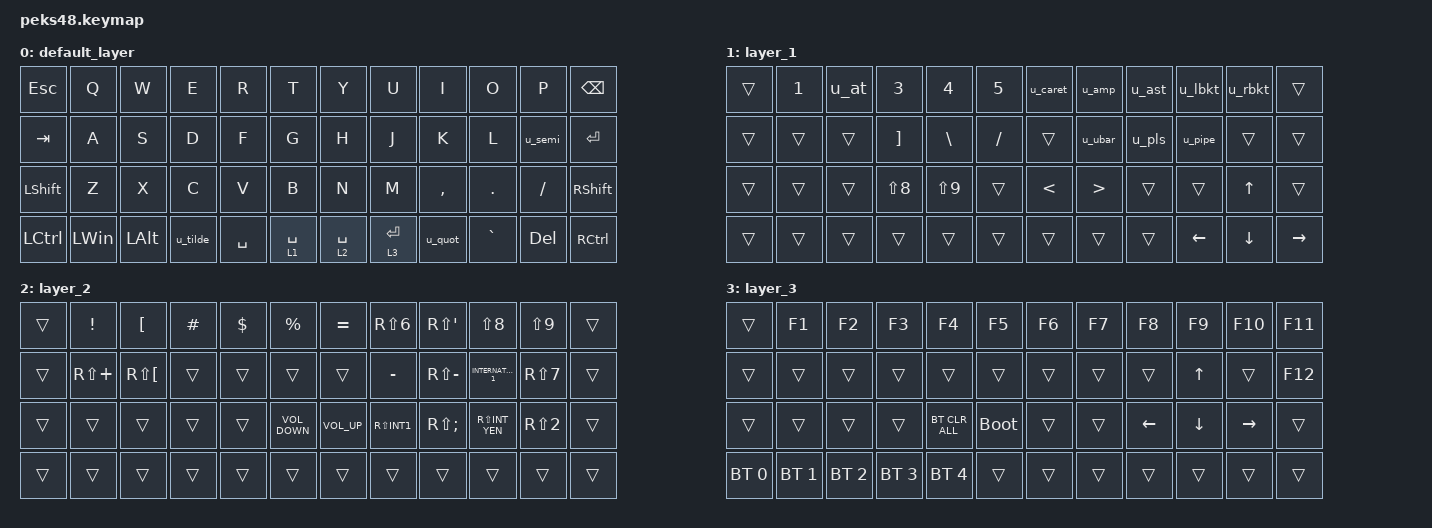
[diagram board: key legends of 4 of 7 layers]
#include <input/processors.dtsi>
#include <dt-bindings/zmk/input_transform.h>
#include <zephyr/dt-bindings/input/input-event-codes.h>
#include <behaviors.dtsi>
#include <dt-bindings/zmk/bt.h>
#include <dt-bindings/zmk/keys.h>
#include <dt-bindings/zmk/pointing.h>

// Conversion definition for using Japanese keyboard with OS settings

#define JP_DQUOTE       AT                // "
#define JP_AMPERSAND    CARET             // &
#define JP_QUOTE        AMPERSAND         // '
#define JP_EQUAL        UNDER             // =
#define JP_CARET        EQUAL             // ^
#define JP_YEN          0x89              // ¥
#define JP_PLUS         COLON             // +
#define JP_TILDE        PLUS              // ~
#define JP_PIPE         LS(0x89)          // |
#define JP_AT           LEFT_BRACKET      // @
#define JP_COLON        SINGLE_QUOTE      // :
#define JP_ASTERISK     DOUBLE_QUOTES     // *
#define JP_BACKQUOTE    LEFT_BRACE        // `
#define JP_UNDERSCORE   LS(0x87)          // _
#define JP_LBRACKET     RIGHT_BRACKET     // [
#define JP_RBRACKET     BACKSLASH         // ]
#define JP_LPAREN       ASTERISK          // (
#define JP_RPAREN       LEFT_PARENTHESIS  // )
#define JP_LBRACE       RIGHT_BRACE       // {
#define JP_RBRACE       PIPE              // }
#define JP_KANA         LANGUAGE_1        // かな
#define JP_EISU         LANGUAGE_2        // 英数
#define JP_HANZEN       GRAVE             // 半角/全角

&mt {
    flavor = "balanced";
    quick-tap-ms = <0>;
};

/ {
    behaviors {
        // 2 と @

        u_at: u_at {
            compatible = "zmk,behavior-mod-morph";
            #binding-cells = <0>;
            bindings = <&kp N2>, <&kp LBKT>;

            mods = <(MOD_LSFT|MOD_RSFT)>;
            label = "2";
        };

        // 6 と ^

        u_caret: u_caret {
            compatible = "zmk,behavior-mod-morph";
            #binding-cells = <0>;
            bindings = <&kp N6>, <&kp EQUAL>;

            mods = <(MOD_LSFT|MOD_RSFT)>;
            label = "6";
        };

        // 7 と &

        u_amp: u_amp {
            compatible = "zmk,behavior-mod-morph";
            #binding-cells = <0>;
            bindings = <&kp N7>, <&kp RS(N6)>;

            mods = <(MOD_LSFT|MOD_RSFT)>;
            label = "7";
        };

        // 8 と *

        u_ast: u_ast {
            compatible = "zmk,behavior-mod-morph";
            #binding-cells = <0>;
            bindings = <&kp N8>, <&kp LS(SQT)>;

            mods = <(MOD_LSFT|MOD_RSFT)>;
            label = "8";
        };

        // 9 と (

        u_lbkt: u_lbkt {
            compatible = "zmk,behavior-mod-morph";
            #binding-cells = <0>;
            bindings = <&kp N9>, <&kp RS(N8)>;

            mods = <(MOD_LSFT|MOD_RSFT)>;
            label = "9";
        };

        // 0 と )

        u_rbkt: u_rbkt {
            compatible = "zmk,behavior-mod-morph";
            #binding-cells = <0>;
            bindings = <&kp N0>, <&kp RS(N9)>;

            mods = <(MOD_LSFT|MOD_RSFT)>;
            label = "0";
        };

        // ; と : (US配列の ;/:)

        u_semi: u_semi {
            compatible = "zmk,behavior-mod-morph";
            #binding-cells = <0>;
            bindings = <&kp SEMI>, <&kp SQT>;

            mods = <(MOD_LSFT|MOD_RSFT)>;
            label = ";";
        };

        // ' と ~

        u_tilde: u_tilde {
            compatible = "zmk,behavior-mod-morph";
            #binding-cells = <0>;
            bindings = <&kp RS(LBKT)>, <&kp RS(PLUS)>;

            mods = <(MOD_LSFT|MOD_RSFT)>;
            label = "`~";
        };

        // ' と "

        u_quot: u_quot {
            compatible = "zmk,behavior-mod-morph";
            #binding-cells = <0>;
            bindings = <&kp RS(N7)>, <&kp RS(N2)>;

            mods = <(MOD_LSFT|MOD_RSFT)>;
            label = "'";
        };

        // - と _

        u_ubar: u_ubar {
            compatible = "zmk,behavior-mod-morph";
            #binding-cells = <0>;
            bindings = <&kp MINUS>, <&kp RS(INTERNATIONAL_1)>;

            mods = <(MOD_LSFT|MOD_RSFT)>;
            label = "-";
        };

        // = と +

        u_pls: u_pls {
            compatible = "zmk,behavior-mod-morph";
            #binding-cells = <0>;
            bindings = <&kp RS(MINUS)>, <&kp RS(SEMICOLON)>;

            mods = <(MOD_LSFT|MOD_RSFT)>;
            label = "=";
        };

        // \ と |

        u_pipe: u_pipe {
            compatible = "zmk,behavior-mod-morph";
            #binding-cells = <0>;
            bindings = <&kp INTERNATIONAL_1>, <&kp RS(INTERNATIONAL_3)>;

            mods = <(MOD_LSFT|MOD_RSFT)>;
            label = "bs";
        };
    };
};

/ {
    keymap {
        compatible = "zmk,keymap";

        default_layer {
            bindings = <
&kp ESC           &kp Q     &kp W         &kp E     &kp R      &kp T          &kp Y        &kp U        &kp I      &kp O      &kp P       &kp BACKSPACE
&kp TAB           &kp A     &kp S         &kp D     &kp F      &kp G          &kp H        &kp J        &kp K      &kp L      &u_semi     &kp ENTER
&kp LEFT_SHIFT    &kp Z     &kp X         &kp C     &kp V      &kp B          &kp N        &kp M        &kp COMMA  &kp DOT    &kp SLASH   &kp RSHIFT
&kp LEFT_CONTROL  &kp LWIN  &kp LEFT_ALT  &u_tilde  &kp SPACE  &lt 1 SPACE    &lt 2 SPACE  &lt 3 ENTER  &u_quot    &kp GRAVE  &kp DELETE  &kp RIGHT_CONTROL
            >;
        };

        layer_1 {
            bindings = <
&trans  &kp N1  &u_at   &kp N3      &kp N4      &kp N5       &u_caret  &u_amp            &u_ast  &u_lbkt         &u_rbkt         &trans
&trans  &trans  &trans  &kp RBKT    &kp BSLH    &kp SLASH    &trans    &u_ubar           &u_pls  &u_pipe         &trans          &trans
&trans  &trans  &trans  &kp LS(N8)  &kp LS(N9)  &trans       &kp LT    &kp GREATER_THAN  &trans  &trans          &kp UP_ARROW    &trans
&trans  &trans  &trans  &trans      &trans      &trans       &trans    &trans            &trans  &kp LEFT_ARROW  &kp DOWN_ARROW  &kp RIGHT_ARROW
            >;
        };

        layer_2 {
            bindings = <
&trans  &kp EXCLAMATION  &kp LBKT      &kp POUND  &kp DOLLAR  &kp PERCENT          &kp EQUAL        &kp RS(N6)    &kp RS(SQT)        &kp LS(N8)           &kp LS(N9)  &trans
&trans  &kp RS(PLUS)     &kp RS(LBKT)  &trans     &trans      &trans               &trans           &kp MINUS     &kp RS(MINUS)      &kp INTERNATIONAL_1  &kp RS(N7)  &trans
&trans  &trans           &trans        &trans     &trans      &kp C_VOLUME_DOWN    &kp C_VOLUME_UP  &kp RS(INT1)  &kp RS(SEMICOLON)  &kp RS(INT_YEN)      &kp RS(N2)  &trans
&trans  &trans           &trans        &trans     &trans      &trans               &trans           &trans        &trans             &trans               &trans      &trans
            >;
        };

        layer_3 {
            bindings = <
&trans        &kp F1        &kp F2        &kp F3        &kp F4          &kp F5         &kp F6  &kp F7  &kp F8          &kp F9          &kp F10          &kp F11
&trans        &trans        &trans        &trans        &trans          &trans         &trans  &trans  &trans          &kp UP_ARROW    &trans           &kp F12
&trans        &trans        &trans        &trans        &bt BT_CLR_ALL  &bootloader    &trans  &trans  &kp LEFT_ARROW  &kp DOWN_ARROW  &kp RIGHT_ARROW  &trans
&bt BT_SEL 0  &bt BT_SEL 1  &bt BT_SEL 2  &bt BT_SEL 3  &bt BT_SEL 4    &trans         &trans  &trans  &trans          &trans          &trans           &trans
            >;
        };

        layer_4 {
            bindings = <
&trans  &trans  &trans  &trans  &trans  &trans    &trans       &bt BT_SEL 0  &bt BT_SEL 1  &bt BT_SEL 2  &bt BT_SEL 3  &bt BT_SEL 4
&trans  &trans  &trans  &trans  &trans  &trans    &trans       &tog 6        &trans        &trans        &trans        &bt BT_CLR
&trans  &trans  &trans  &trans  &trans  &trans    &bootloader  &trans        &trans        &trans        &trans        &bt BT_CLR_ALL
&trans  &trans  &trans  &trans
            >;
        };

        layer_5 {
            bindings = <
&trans  &trans  &trans    &trans    &trans    &trans    &trans  &trans    &trans    &trans    &trans  &trans
&trans  &trans  &mkp MB3  &mkp MB2  &mkp MB1  &trans    &trans  &mkp MB1  &mkp MB2  &mkp MB3  &trans  &trans
&trans  &trans  &trans    &trans    &trans    &trans    &trans  &trans    &trans    &trans    &trans  &trans
&trans  &trans  &trans    &trans
            >;
        };

        layer_6 {
            bindings = <
&trans  &trans  &trans  &trans  &trans  &trans    &trans  &trans  &trans    &trans    &trans    &trans
&trans  &trans  &trans  &trans  &trans  &trans    &trans  &trans  &mkp MB1  &mkp MB3  &mkp MB2  &trans
&trans  &trans  &trans  &trans  &trans  &trans    &trans  &trans  &trans    &trans    &trans    &trans
&trans  &trans  &trans  &trans
            >;
        };
    };
};
